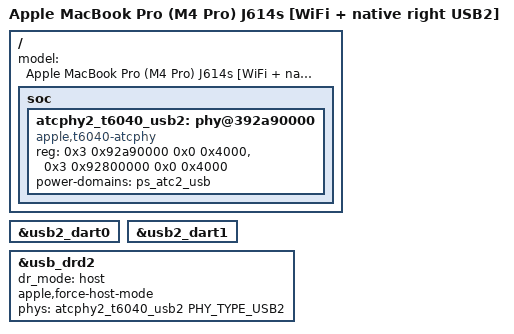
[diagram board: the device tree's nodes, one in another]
// SPDX-License-Identifier: GPL-2.0+ OR MIT
/*
 * T6040 J614s integration candidate: proven PCIe/WiFi/BT path plus native
 * USB2 host on the right Type-C port.
 *
 * The USB delta remains deliberately high-speed-only. It does not describe a
 * USB3 PHY, ATC reset-controller relationship, I2C6 retimer, role switch, or
 * another Type-C port. The native PHY power_on callback performs volatile
 * eUSB2 MMIO writes and therefore remains behind exact review and an attended
 * live ticket.
 */

#include <dt-bindings/phy/phy.h>

#include "t6040-j614s-dcuart-wifi.dts"

/ {
	model = "Apple MacBook Pro (M4 Pro) J614s [WiFi + native right USB2]";

	soc {
		atcphy2_t6040_usb2: phy@392a90000 {
			compatible = "apple,t6040-atcphy";
			reg = <0x3 0x92a90000 0x0 0x4000>,
			      <0x3 0x92800000 0x0 0x4000>;
			reg-names = "bank0", "bank1";
			#phy-cells = <1>;
			power-domains = <&ps_atc2_usb>;
			status = "okay";
		};
	};
};

&usb2_dart0 {
	status = "okay";
};

&usb2_dart1 {
	status = "okay";
};

&usb_drd2 {
	/delete-property/ apple,force-device-mode;
	dr_mode = "host";
	apple,force-host-mode;
	phys = <&atcphy2_t6040_usb2 PHY_TYPE_USB2>;
	phy-names = "usb2-phy";
	status = "okay";
};
